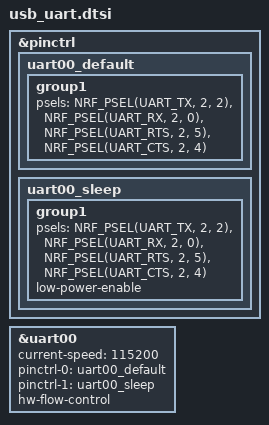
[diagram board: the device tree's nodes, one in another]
&pinctrl {
	/omit-if-no-ref/ uart00_default: uart00_default {
		group1 {
			psels = <NRF_PSEL(UART_TX, 2, 2)>, <NRF_PSEL(UART_RX, 2, 0)>, <NRF_PSEL(UART_RTS, 2, 5)>, <NRF_PSEL(UART_CTS, 2, 4)>;
		};
	};

	/omit-if-no-ref/ uart00_sleep: uart00_sleep {
		group1 {
			psels = <NRF_PSEL(UART_TX, 2, 2)>, <NRF_PSEL(UART_RX, 2, 0)>, <NRF_PSEL(UART_RTS, 2, 5)>, <NRF_PSEL(UART_CTS, 2, 4)>;
			low-power-enable;
		};
	};
};
&uart00 { 
	status = "okay"; 
	//current-speed = <14400>;/*115200*/
	current-speed = <115200>;/*921600*/
	//current-speed = <57600>;/*460800*/
	pinctrl-0 = <&uart00_default>;
	pinctrl-1 = <&uart00_sleep>;
	pinctrl-names = "default", "sleep";
	hw-flow-control;
};
